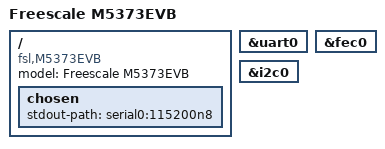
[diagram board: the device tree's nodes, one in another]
// SPDX-License-Identifier: GPL-2.0+
/*
 * Copyright (C) 2018 Angelo Dureghello <angelo@sysam.it>
 */

/dts-v1/;
/include/ "mcf537x.dtsi"

/ {
	model = "Freescale M5373EVB";
	compatible = "fsl,M5373EVB";

	chosen {
		stdout-path = "serial0:115200n8";
	};
};

&uart0 {
	bootph-all;
	status = "okay";
};

&fec0 {
	status = "okay";
};

&i2c0 {
	status = "okay";
};
